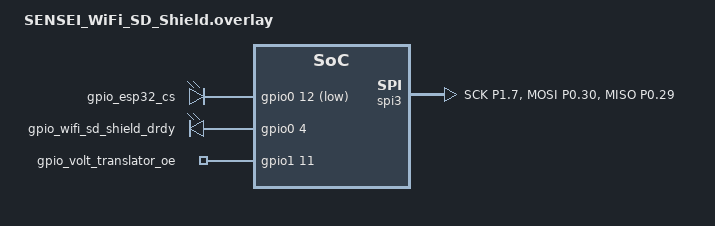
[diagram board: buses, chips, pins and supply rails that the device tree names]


/*
 * Copyright (c) 2022 Nordic Semiconductor ASA
 *
 * SPDX-License-Identifier: LicenseRef-Nordic-5-Clause
 */


/ {
	gpio_leds {
		compatible = "gpio-leds";

		gpio_esp32_cs: gpio_esp32_cs {
			gpios = <&gpio0 12 GPIO_ACTIVE_LOW>;
		};

		gpio_wifi_sd_shield_drdy: gpio_wifi_sd_shield_drdy {
			gpios = <&gpio0 4 GPIO_ACTIVE_HIGH>;
		};

		gpio_volt_translator_oe: gpio_volt_translator_oe {
			gpios = <&gpio1 11 GPIO_ACTIVE_HIGH>;
		};

	};
};


&spi3 {
    compatible = "nordic,nrf-spim";
	status = "okay";
	pinctrl-0 = <&spi3_default>;
	pinctrl-1 = <&spi3_sleep>;
	pinctrl-names = "default", "sleep";
	cs-gpios = <&gpio0 12 GPIO_ACTIVE_LOW>;
};

&pinctrl {
	spi3_default: spi3_default {
		group1 {
				psels = <NRF_PSEL(SPIM_SCK, 1, 7)>,
				<NRF_PSEL(SPIM_MOSI, 0, 30)>,
				<NRF_PSEL(SPIM_MISO, 0, 29)>;
		};
	};

	spi3_sleep: spi3_sleep {
		group1 {
				psels = <NRF_PSEL(SPIM_SCK, 1, 7)>,
				<NRF_PSEL(SPIM_MOSI, 0, 30)>,
				<NRF_PSEL(SPIM_MISO, 0, 29)>;
				low-power-enable;
		};
	};
};

